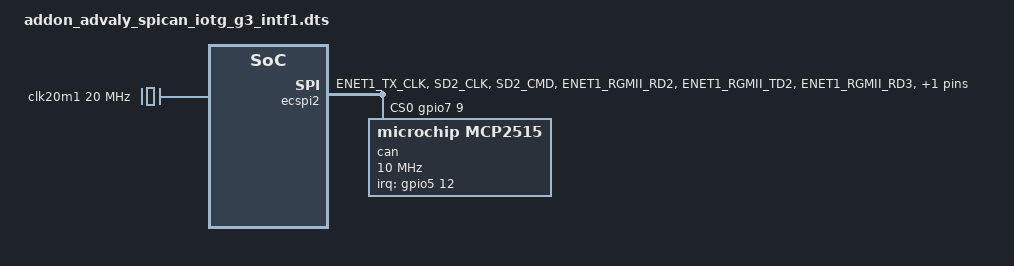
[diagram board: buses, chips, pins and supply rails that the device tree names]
/*
 * Copyright (C) 2019 Atmark Techno, Inc. All Rights Reserved.
 * Author: Daisuke Mizobuchi <mizo@atmark-techno.com>
 *
 * This program is free software; you can redistribute it and/or
 * modify it under the terms of the GNU General Public License
 * version 2 as published by the Free Software Foundation.
 */

#include <dt-bindings/clock/imx7d-clock.h>
#include <dt-bindings/interrupt-controller/irq.h>
#include "../../../../arch/arm/boot/dts/imx7d-pinfunc.h"

/dts-v1/;
/plugin/;
/ {
	fragment@0 {
		target = <&iomuxc>;
		__overlay__ {
			addon-intf1 {
				pinctrl_ecspi2: ecspi2grp {
					fsl,pins = <
						MX7D_PAD_ENET1_TX_CLK__GPIO7_IO12	0x00	/* INTF1_32 */
						MX7D_PAD_SD2_CLK__GPIO5_IO12		0x70	/* INTF1_47 */
						MX7D_PAD_SD2_CMD__GPIO5_IO13		0x00	/* INTF1_48 */

						MX7D_PAD_ENET1_RGMII_RD2__ECSPI2_SCLK	0x70	/* INTF1_35 */
						MX7D_PAD_ENET1_RGMII_TD2__ECSPI2_MISO	0x70	/* INTF1_36 */
						MX7D_PAD_ENET1_RGMII_RD3__ECSPI2_MOSI	0x70	/* INTF1_37 */
						MX7D_PAD_ENET1_RGMII_TD3__GPIO7_IO9	0x70	/* INTF1_50 */
					>;
				};
			};
		};
	};

	fragment@1 {
		target-path = "/";
		__overlay__ {
			clk20m1: dummy@1 {
				compatible = "fixed-clock";
				#clock-cells = <0>;
				clock-frequency = <20000000>;
				clock-output-names = "clk20m1";
			};
		};
	};

	fragment@2 {
		target = <&ecspi2>;
		__overlay__ {
			pinctrl-names = "default";
			pinctrl-0 = <&pinctrl_ecspi2>;
			fsl,spi-num-chipselects = <1>;
			cs-gpios = <&gpio7 9 0>;
			status = "okay";

			#address-cells = <1>;
			#size-cells = <0>;
			can@0 {
				compatible = "microchip,mcp2515";
				reg = <0>;
				clocks = <&clk20m1>;
				spi-max-frequency = <10000000>;
				interrupt-parent = <&gpio5>;
				interrupts = <12 IRQ_TYPE_EDGE_FALLING>;
			};
		};
	};
};
